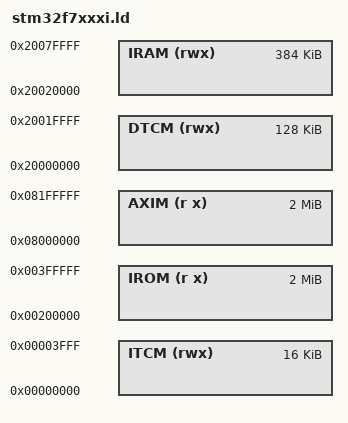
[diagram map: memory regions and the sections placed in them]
MEMORY
{
	ITCM	(rwx) : ORIGIN = 0x00000000, LENGTH = 16k
    IROM    (r x) : ORIGIN = 0x00200000, LENGTH = 2048k
    AXIM	(r x) : ORIGIN = 0x08000000, LENGTH = 2048k
    DTCM    (rwx) : ORIGIN = 0x20000000, LENGTH = 128k
    IRAM    (rwx) : ORIGIN = 0x20020000, LENGTH = 384k
}

INCLUDE stm32f7.ld
